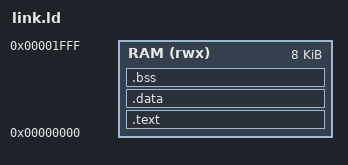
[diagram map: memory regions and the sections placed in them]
/* SPDX-License-Identifier: CERN-OHL-W-2.0 */
OUTPUT_ARCH("riscv")
ENTRY(_start)
MEMORY { RAM (rwx) : ORIGIN = 0x0, LENGTH = 8K }
SECTIONS {
  .text : { *(.text.start) *(.text*) *(.rodata*) *(.srodata*) } > RAM
  .data : { *(.data*) *(.sdata*) } > RAM
  .bss : { . = ALIGN(4); _bss_start = .; *(.bss*) *(.sbss*) *(COMMON) . = ALIGN(4); _bss_end = .; } > RAM
  _stack_top = ORIGIN(RAM) + LENGTH(RAM);
}
